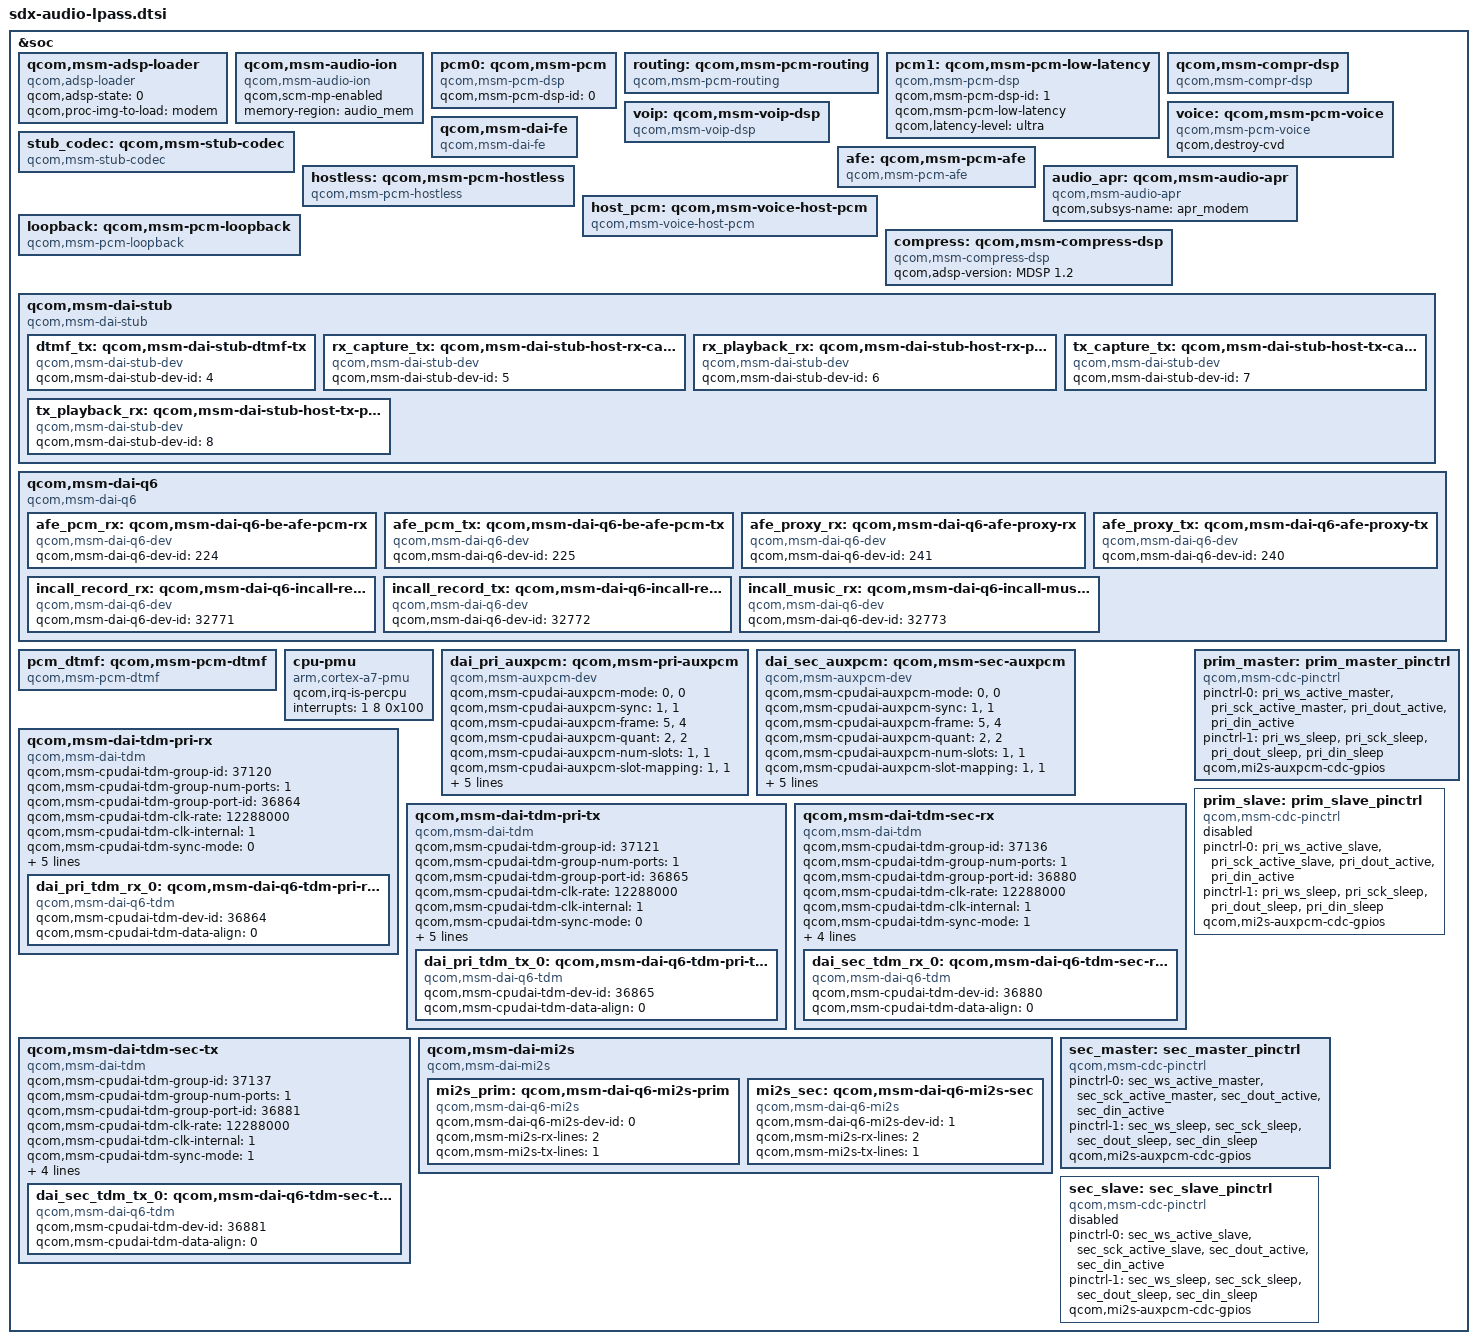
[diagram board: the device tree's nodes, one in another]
/*
 * Copyright (c) 2015-2019, The Linux Foundation. All rights reserved.
 *
 * This program is free software; you can redistribute it and/or modify
 * it under the terms of the GNU General Public License version 2 and
 * only version 2 as published by the Free Software Foundation.
 *
 * This program is distributed in the hope that it will be useful,
 * but WITHOUT ANY WARRANTY; without even the implied warranty of
 * MERCHANTABILITY or FITNESS FOR A PARTICULAR PURPOSE.  See the
 * GNU General Public License for more details.
 */

&soc {
	qcom,msm-adsp-loader {
		compatible = "qcom,adsp-loader";
		qcom,adsp-state = <0>;
		qcom,proc-img-to-load = "modem";
	};

	qcom,msm-audio-ion {
		compatible = "qcom,msm-audio-ion";
		qcom,scm-mp-enabled;
		memory-region = <&audio_mem>;
	};

	pcm0: qcom,msm-pcm {
		compatible = "qcom,msm-pcm-dsp";
		qcom,msm-pcm-dsp-id = <0>;
	};

	routing: qcom,msm-pcm-routing {
		compatible = "qcom,msm-pcm-routing";
	};

	pcm1: qcom,msm-pcm-low-latency {
		compatible = "qcom,msm-pcm-dsp";
		qcom,msm-pcm-dsp-id = <1>;
		qcom,msm-pcm-low-latency;
		qcom,latency-level = "ultra";
	};

	qcom,msm-compr-dsp {
		compatible = "qcom,msm-compr-dsp";
	};

	voip: qcom,msm-voip-dsp {
		compatible = "qcom,msm-voip-dsp";
	};

	voice: qcom,msm-pcm-voice {
		compatible = "qcom,msm-pcm-voice";
		qcom,destroy-cvd;
	};

	stub_codec: qcom,msm-stub-codec {
		compatible = "qcom,msm-stub-codec";
	};

	qcom,msm-dai-fe {
		compatible = "qcom,msm-dai-fe";
	};

	afe: qcom,msm-pcm-afe {
		compatible = "qcom,msm-pcm-afe";
	};

	 hostless: qcom,msm-pcm-hostless {
		compatible = "qcom,msm-pcm-hostless";
	};

	audio_apr: qcom,msm-audio-apr {
		compatible = "qcom,msm-audio-apr";
		qcom,subsys-name = "apr_modem";
	};

	host_pcm: qcom,msm-voice-host-pcm {
		compatible = "qcom,msm-voice-host-pcm";
	};

	loopback: qcom,msm-pcm-loopback {
		compatible = "qcom,msm-pcm-loopback";
	};

	compress: qcom,msm-compress-dsp {
		compatible = "qcom,msm-compress-dsp";
		qcom,adsp-version = "MDSP 1.2";
	};

	qcom,msm-dai-stub {
		compatible = "qcom,msm-dai-stub";
		dtmf_tx: qcom,msm-dai-stub-dtmf-tx {
			compatible = "qcom,msm-dai-stub-dev";
			qcom,msm-dai-stub-dev-id = <4>;
		};

		rx_capture_tx: qcom,msm-dai-stub-host-rx-capture-tx {
			compatible = "qcom,msm-dai-stub-dev";
			qcom,msm-dai-stub-dev-id = <5>;
		};

		rx_playback_rx: qcom,msm-dai-stub-host-rx-playback-rx {
			compatible = "qcom,msm-dai-stub-dev";
			qcom,msm-dai-stub-dev-id = <6>;
		};

		tx_capture_tx: qcom,msm-dai-stub-host-tx-capture-tx {
			compatible = "qcom,msm-dai-stub-dev";
			qcom,msm-dai-stub-dev-id = <7>;
		};

		tx_playback_rx: qcom,msm-dai-stub-host-tx-playback-rx {
			compatible = "qcom,msm-dai-stub-dev";
			qcom,msm-dai-stub-dev-id = <8>;
		};
	};

	qcom,msm-dai-q6 {
		compatible = "qcom,msm-dai-q6";
		afe_pcm_rx: qcom,msm-dai-q6-be-afe-pcm-rx {
			compatible = "qcom,msm-dai-q6-dev";
			qcom,msm-dai-q6-dev-id = <224>;
		};

		afe_pcm_tx: qcom,msm-dai-q6-be-afe-pcm-tx {
			compatible = "qcom,msm-dai-q6-dev";
			qcom,msm-dai-q6-dev-id = <225>;
		};

		afe_proxy_rx: qcom,msm-dai-q6-afe-proxy-rx {
			compatible = "qcom,msm-dai-q6-dev";
			qcom,msm-dai-q6-dev-id = <241>;
		};

		afe_proxy_tx: qcom,msm-dai-q6-afe-proxy-tx {
			compatible = "qcom,msm-dai-q6-dev";
			qcom,msm-dai-q6-dev-id = <240>;
		};

		incall_record_rx: qcom,msm-dai-q6-incall-record-rx {
			compatible = "qcom,msm-dai-q6-dev";
			qcom,msm-dai-q6-dev-id = <32771>;
		};

		incall_record_tx: qcom,msm-dai-q6-incall-record-tx {
			compatible = "qcom,msm-dai-q6-dev";
			qcom,msm-dai-q6-dev-id = <32772>;
		};

		incall_music_rx: qcom,msm-dai-q6-incall-music-rx {
			compatible = "qcom,msm-dai-q6-dev";
			qcom,msm-dai-q6-dev-id = <32773>;
		};
	};

	pcm_dtmf: qcom,msm-pcm-dtmf {
		compatible = "qcom,msm-pcm-dtmf";
	};

	cpu-pmu {
		compatible = "arm,cortex-a7-pmu";
		qcom,irq-is-percpu;
		interrupts = <1 8 0x100>;
	};

	dai_pri_auxpcm: qcom,msm-pri-auxpcm {
		compatible = "qcom,msm-auxpcm-dev";
		qcom,msm-cpudai-auxpcm-mode = <0>, <0>;
		qcom,msm-cpudai-auxpcm-sync = <1>, <1>;
		qcom,msm-cpudai-auxpcm-frame = <5>, <4>;
		qcom,msm-cpudai-auxpcm-quant = <2>, <2>;
		qcom,msm-cpudai-auxpcm-num-slots = <1>, <1>;
		qcom,msm-cpudai-auxpcm-slot-mapping = <1>, <1>;
		qcom,msm-cpudai-auxpcm-data = <0>, <0>;
		qcom,msm-cpudai-auxpcm-pcm-clk-rate = <2048000>, <2048000>;
		qcom,msm-auxpcm-interface = "primary";
		qcom,msm-cpudai-afe-clk-ver = <2>;
	};

	dai_sec_auxpcm: qcom,msm-sec-auxpcm {
		compatible = "qcom,msm-auxpcm-dev";
		qcom,msm-cpudai-auxpcm-mode = <0>, <0>;
		qcom,msm-cpudai-auxpcm-sync = <1>, <1>;
		qcom,msm-cpudai-auxpcm-frame = <5>, <4>;
		qcom,msm-cpudai-auxpcm-quant = <2>, <2>;
		qcom,msm-cpudai-auxpcm-num-slots = <1>, <1>;
		qcom,msm-cpudai-auxpcm-slot-mapping = <1>, <1>;
		qcom,msm-cpudai-auxpcm-data = <0>, <0>;
		qcom,msm-cpudai-auxpcm-pcm-clk-rate = <2048000>, <2048000>;
		qcom,msm-auxpcm-interface = "secondary";
		qcom,msm-cpudai-afe-clk-ver = <2>;
	};

	qcom,msm-dai-tdm-pri-rx {
		compatible = "qcom,msm-dai-tdm";
		qcom,msm-cpudai-tdm-group-id = <37120>;
		qcom,msm-cpudai-tdm-group-num-ports = <1>;
		qcom,msm-cpudai-tdm-group-port-id = <36864>;
		qcom,msm-cpudai-tdm-clk-rate = <12288000>;
		qcom,msm-cpudai-tdm-clk-internal = <1>;
		qcom,msm-cpudai-tdm-sync-mode = <0>;
		qcom,msm-cpudai-tdm-sync-src = <1>;
		qcom,msm-cpudai-tdm-data-out = <0>;
		qcom,msm-cpudai-tdm-invert-sync = <0>;
		qcom,msm-cpudai-tdm-data-delay = <1>;
		qcom,msm-cpudai-tdm-clk-attribute = /bits/ 16 <1>;
		dai_pri_tdm_rx_0: qcom,msm-dai-q6-tdm-pri-rx-0 {
			compatible = "qcom,msm-dai-q6-tdm";
			qcom,msm-cpudai-tdm-dev-id = <36864>;
			qcom,msm-cpudai-tdm-data-align = <0>;
		};

	};

	qcom,msm-dai-tdm-pri-tx {
		compatible = "qcom,msm-dai-tdm";
		qcom,msm-cpudai-tdm-group-id = <37121>;
		qcom,msm-cpudai-tdm-group-num-ports = <1>;
		qcom,msm-cpudai-tdm-group-port-id = <36865>;
		qcom,msm-cpudai-tdm-clk-rate = <12288000>;
		qcom,msm-cpudai-tdm-clk-internal = <1>;
		qcom,msm-cpudai-tdm-sync-mode = <0>;
		qcom,msm-cpudai-tdm-sync-src = <1>;
		qcom,msm-cpudai-tdm-data-out = <0>;
		qcom,msm-cpudai-tdm-invert-sync = <0>;
		qcom,msm-cpudai-tdm-data-delay = <1>;
		qcom,msm-cpudai-tdm-clk-attribute = /bits/ 16 <1>;
		dai_pri_tdm_tx_0: qcom,msm-dai-q6-tdm-pri-tx-0 {
			compatible = "qcom,msm-dai-q6-tdm";
			qcom,msm-cpudai-tdm-dev-id = <36865>;
			qcom,msm-cpudai-tdm-data-align = <0>;
		};
	};

	qcom,msm-dai-tdm-sec-rx {
		compatible = "qcom,msm-dai-tdm";
		qcom,msm-cpudai-tdm-group-id = <37136>;
		qcom,msm-cpudai-tdm-group-num-ports = <1>;
		qcom,msm-cpudai-tdm-group-port-id = <36880>;
		qcom,msm-cpudai-tdm-clk-rate = <12288000>;
		qcom,msm-cpudai-tdm-clk-internal = <1>;
		qcom,msm-cpudai-tdm-sync-mode = <1>;
		qcom,msm-cpudai-tdm-sync-src = <0>;
		qcom,msm-cpudai-tdm-data-out = <0>;
		qcom,msm-cpudai-tdm-invert-sync = <0>;
		qcom,msm-cpudai-tdm-data-delay = <0>;
		dai_sec_tdm_rx_0: qcom,msm-dai-q6-tdm-sec-rx-0 {
			compatible = "qcom,msm-dai-q6-tdm";
			qcom,msm-cpudai-tdm-dev-id = <36880>;
			qcom,msm-cpudai-tdm-data-align = <0>;
		};
	};

	qcom,msm-dai-tdm-sec-tx {
		compatible = "qcom,msm-dai-tdm";
		qcom,msm-cpudai-tdm-group-id = <37137>;
		qcom,msm-cpudai-tdm-group-num-ports = <1>;
		qcom,msm-cpudai-tdm-group-port-id = <36881>;
		qcom,msm-cpudai-tdm-clk-rate = <12288000>;
		qcom,msm-cpudai-tdm-clk-internal = <1>;
		qcom,msm-cpudai-tdm-sync-mode = <1>;
		qcom,msm-cpudai-tdm-sync-src = <0>;
		qcom,msm-cpudai-tdm-data-out = <0>;
		qcom,msm-cpudai-tdm-invert-sync = <0>;
		qcom,msm-cpudai-tdm-data-delay = <0>;
		dai_sec_tdm_tx_0: qcom,msm-dai-q6-tdm-sec-tx-0 {
			compatible = "qcom,msm-dai-q6-tdm";
			qcom,msm-cpudai-tdm-dev-id = <36881>;
			qcom,msm-cpudai-tdm-data-align = <0>;
		};
	};

	qcom,msm-dai-mi2s {
		compatible = "qcom,msm-dai-mi2s";
		mi2s_prim: qcom,msm-dai-q6-mi2s-prim {
			compatible = "qcom,msm-dai-q6-mi2s";
			qcom,msm-dai-q6-mi2s-dev-id = <0>;
			qcom,msm-mi2s-rx-lines = <2>;
			qcom,msm-mi2s-tx-lines = <1>;
		};
		mi2s_sec: qcom,msm-dai-q6-mi2s-sec {
			compatible = "qcom,msm-dai-q6-mi2s";
			qcom,msm-dai-q6-mi2s-dev-id = <1>;
			qcom,msm-mi2s-rx-lines = <2>;
			qcom,msm-mi2s-tx-lines = <1>;
		};

	};

	prim_master: prim_master_pinctrl {
		compatible = "qcom,msm-cdc-pinctrl";
		pinctrl-names = "aud_active", "aud_sleep";
		pinctrl-0 = <&pri_ws_active_master
				&pri_sck_active_master
				&pri_dout_active
				&pri_din_active>;
		pinctrl-1 = <&pri_ws_sleep
				&pri_sck_sleep
				&pri_dout_sleep
				&pri_din_sleep>;
		qcom,mi2s-auxpcm-cdc-gpios;
	};

	prim_slave: prim_slave_pinctrl {
		status = "disabled";
		compatible = "qcom,msm-cdc-pinctrl";
		pinctrl-names = "aud_active", "aud_sleep";
		pinctrl-0 = <&pri_ws_active_slave
				&pri_sck_active_slave
				&pri_dout_active
				&pri_din_active>;
		pinctrl-1 = <&pri_ws_sleep
				&pri_sck_sleep
				&pri_dout_sleep
				&pri_din_sleep>;
		qcom,mi2s-auxpcm-cdc-gpios;
	};

	sec_master: sec_master_pinctrl {
		compatible = "qcom,msm-cdc-pinctrl";
		pinctrl-names = "aud_active", "aud_sleep";
		pinctrl-0 = <&sec_ws_active_master
				&sec_sck_active_master
				&sec_dout_active
				&sec_din_active>;
		pinctrl-1 = <&sec_ws_sleep
				&sec_sck_sleep
				&sec_dout_sleep
				&sec_din_sleep>;
		qcom,mi2s-auxpcm-cdc-gpios;
	};

	sec_slave: sec_slave_pinctrl {
		status = "disabled";
		compatible = "qcom,msm-cdc-pinctrl";
		pinctrl-names = "aud_active", "aud_sleep";
		pinctrl-0 = <&sec_ws_active_slave
				&sec_sck_active_slave
				&sec_dout_active
				&sec_din_active>;
		pinctrl-1 = <&sec_ws_sleep
				&sec_sck_sleep
				&sec_dout_sleep
				&sec_din_sleep>;
		qcom,mi2s-auxpcm-cdc-gpios;
	};
};
